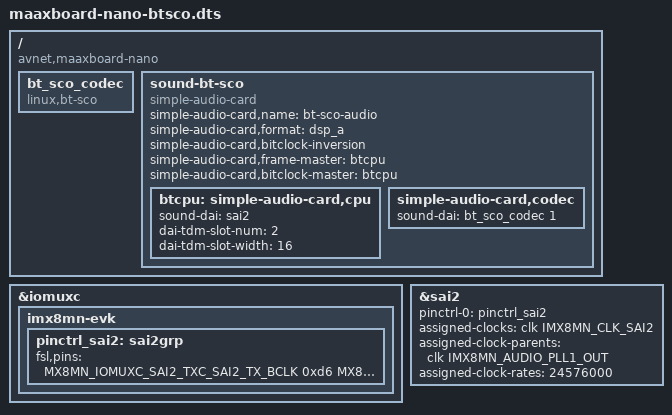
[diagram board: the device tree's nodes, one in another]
/*
 * Copyright 2021 AVNET
 *
 * This program is free software; you can redistribute it and/or
 * modify it under the terms of the GNU General Public License
 * as published by the Free Software Foundation; either version 2
 * of the License, or (at your option) any later version.
 *
 * This program is distributed in the hope that it will be useful,
 * but WITHOUT ANY WARRANTY; without even the implied warranty of
 * MERCHANTABILITY or FITNESS FOR A PARTICULAR PURPOSE.  See the
 * GNU General Public License for more details.
 */

/dts-v1/;
/plugin/;

#include <dt-bindings/clock/imx8mn-clock.h>
#include "../imx8mn-pinfunc.h"

/* 4 x silicon digital microphones */

/ {
	compatible = "avnet,maaxboard-nano", "fsl,imx8mn";

	fragment@0 {
		target = <&iomuxc>;
		__overlay__ {
			imx8mn-evk {
			  	pinctrl_sai2: sai2grp {
					fsl,pins = <
						MX8MN_IOMUXC_SAI2_TXC_SAI2_TX_BCLK      0xd6
						MX8MN_IOMUXC_SAI2_TXFS_SAI2_TX_SYNC     0xd6
						MX8MN_IOMUXC_SAI2_TXD0_SAI2_TX_DATA0    0xd6
						MX8MN_IOMUXC_SAI2_RXD0_SAI2_RX_DATA0    0xd6
					>;
				};
			};
		};
	};

	fragment@1 {
		target = <&sai2>;
		__overlay__ {
				#sound-dai-cells = <0>;
				pinctrl-names = "default";
				pinctrl-0 = <&pinctrl_sai2>;
				assigned-clocks = <&clk IMX8MN_CLK_SAI2>;
				assigned-clock-parents = <&clk IMX8MN_AUDIO_PLL1_OUT>;
				assigned-clock-rates = <24576000>;
				status = "okay";
		};
	};

	fragment@2 {
		target-path = "/";
		__overlay__ {
			bt_sco_codec: bt_sco_codec {
				#sound-dai-cells = <1>;
				compatible = "linux,bt-sco";
			};

			sound-bt-sco {
				compatible = "simple-audio-card";
				simple-audio-card,name = "bt-sco-audio";
				simple-audio-card,format = "dsp_a";
				simple-audio-card,bitclock-inversion;
				simple-audio-card,frame-master = <&btcpu>;
				simple-audio-card,bitclock-master = <&btcpu>;

				btcpu: simple-audio-card,cpu {
					sound-dai = <&sai2>;
					dai-tdm-slot-num = <2>;
					dai-tdm-slot-width = <16>;
				};

				simple-audio-card,codec {
					sound-dai = <&bt_sco_codec 1>;
				};
			};
		};
	};
};
